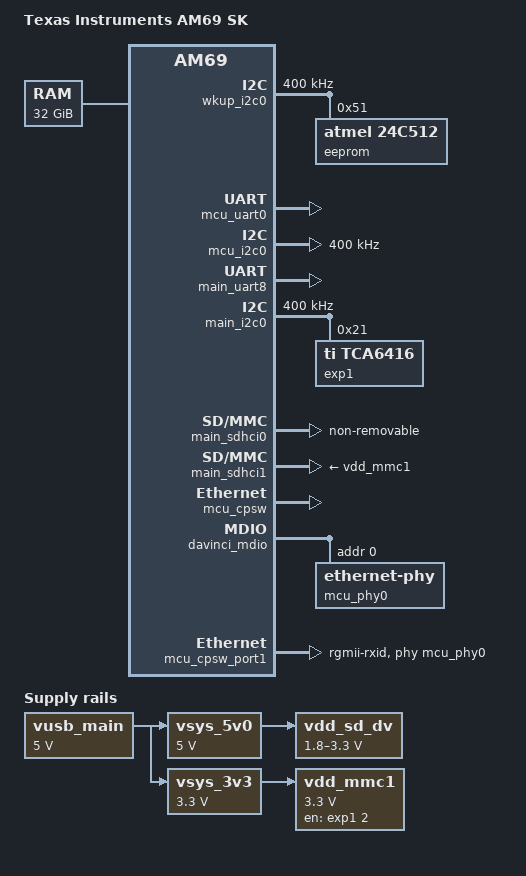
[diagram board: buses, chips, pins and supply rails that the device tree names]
/dts-v1/;
#include <dt-bindings/net/ti-dp83867.h>
#include <dt-bindings/gpio/gpio.h>
#include "k3-j784s4.dtsi"
/ {
	compatible = "ti,am69-sk", "ti,j784s4";
	model = "Texas Instruments AM69 SK";
	chosen {
		stdout-path = "serial2:115200n8";
	};
	aliases {
		serial0 = &wkup_uart0;
		serial1 = &mcu_uart0;
		serial2 = &main_uart8;
		mmc0 = &main_sdhci0;
		mmc1 = &main_sdhci1;
		i2c0 = &wkup_i2c0;
		i2c3 = &main_i2c0;
		ethernet0 = &mcu_cpsw_port1;
	};
	memory@80000000 {
		device_type = "memory";
		reg = <0x00 0x80000000 0x00 0x80000000>,
		      <0x08 0x80000000 0x07 0x80000000>;
	};
	reserved_memory: reserved-memory {
		#address-cells = <2>;
		#size-cells = <2>;
		ranges;
		secure_ddr: optee@9e800000 {
			reg = <0x00 0x9e800000 0x00 0x01800000>;
			no-map;
		};
	};
	vusb_main: regulator-vusb-main5v0 {
		compatible = "regulator-fixed";
		regulator-name = "vusb-main5v0";
		regulator-min-microvolt = <5000000>;
		regulator-max-microvolt = <5000000>;
		regulator-always-on;
		regulator-boot-on;
	};
	vsys_5v0: regulator-vsys5v0 {
		compatible = "regulator-fixed";
		regulator-name = "vsys_5v0";
		regulator-min-microvolt = <5000000>;
		regulator-max-microvolt = <5000000>;
		vin-supply = <&vusb_main>;
		regulator-always-on;
		regulator-boot-on;
	};
	vsys_3v3: regulator-vsys3v3 {
		compatible = "regulator-fixed";
		regulator-name = "vsys_3v3";
		regulator-min-microvolt = <3300000>;
		regulator-max-microvolt = <3300000>;
		vin-supply = <&vusb_main>;
		regulator-always-on;
		regulator-boot-on;
	};
	vdd_mmc1: regulator-sd {
		compatible = "regulator-fixed";
		regulator-name = "vdd_mmc1";
		regulator-min-microvolt = <3300000>;
		regulator-max-microvolt = <3300000>;
		regulator-boot-on;
		enable-active-high;
		vin-supply = <&vsys_3v3>;
		gpio = <&exp1 2 GPIO_ACTIVE_HIGH>;
	};
	vdd_sd_dv: regulator-tlv71033 {
		compatible = "regulator-gpio";
		regulator-name = "tlv71033";
		pinctrl-names = "default";
		pinctrl-0 = <&vdd_sd_dv_pins_default>;
		regulator-min-microvolt = <1800000>;
		regulator-max-microvolt = <3300000>;
		regulator-boot-on;
		vin-supply = <&vsys_5v0>;
		gpios = <&main_gpio0 49 GPIO_ACTIVE_HIGH>;
		states = <1800000 0x0>,
			 <3300000 0x1>;
	};
};
&main_pmx0 {
	bootph-all;
	main_uart8_pins_default: main-uart8-default-pins {
		bootph-all;
		pinctrl-single,pins = <
			J784S4_IOPAD(0x0d0, PIN_INPUT, 11)  
			J784S4_IOPAD(0x0d4, PIN_OUTPUT, 11)  
		>;
	};
	main_i2c0_pins_default: main-i2c0-default-pins {
		pinctrl-single,pins = <
			J784S4_IOPAD(0x0e0, PIN_INPUT_PULLUP, 0)  
			J784S4_IOPAD(0x0e4, PIN_INPUT_PULLUP, 0)  
		>;
	};
	main_mmc1_pins_default: main-mmc1-default-pins {
		bootph-all;
		pinctrl-single,pins = <
			J784S4_IOPAD(0x104, PIN_INPUT, 0)  
			J784S4_IOPAD(0x108, PIN_INPUT, 0)  
			J784S4_IOPAD(0x100, PIN_INPUT, 0)  
			J784S4_IOPAD(0x0fc, PIN_INPUT, 0)  
			J784S4_IOPAD(0x0f8, PIN_INPUT, 0)  
			J784S4_IOPAD(0x0f4, PIN_INPUT, 0)  
			J784S4_IOPAD(0x0f0, PIN_INPUT, 0)  
			J784S4_IOPAD(0x0e8, PIN_INPUT, 8)  
		>;
	};
	vdd_sd_dv_pins_default: vdd-sd-dv-default-pins {
		pinctrl-single,pins = <
			J784S4_IOPAD(0x0C4, PIN_INPUT, 7)  
		>;
	};
	rpi_header_gpio0_pins_default: rpi-header-gpio0-default-pins {
		pinctrl-single,pins = <
			J784S4_IOPAD(0x0BC, PIN_INPUT, 7)  
			J784S4_IOPAD(0x06C, PIN_INPUT, 7)  
			J784S4_IOPAD(0x0B4, PIN_INPUT, 7)  
			J784S4_IOPAD(0x0C0, PIN_INPUT, 7)  
			J784S4_IOPAD(0x00C, PIN_INPUT, 7)  
			J784S4_IOPAD(0x0B8, PIN_INPUT, 7)  
			J784S4_IOPAD(0x090, PIN_INPUT, 7)  
			J784S4_IOPAD(0x0A8, PIN_INPUT, 7)  
			J784S4_IOPAD(0x0A4, PIN_INPUT, 7)  
			J784S4_IOPAD(0x034, PIN_INPUT, 7)  
			J784S4_IOPAD(0x0CC, PIN_INPUT, 7)  
			J784S4_IOPAD(0x08C, PIN_INPUT, 7)  
			J784S4_IOPAD(0x008, PIN_INPUT, 7)  
			J784S4_IOPAD(0x004, PIN_INPUT, 7)  
		>;
	};
};
&wkup_pmx2 {
	bootph-all;
	wkup_uart0_pins_default: wkup-uart0-default-pins {
		bootph-all;
		pinctrl-single,pins = <
			J721S2_WKUP_IOPAD(0x070, PIN_INPUT, 0)  
			J721S2_WKUP_IOPAD(0x074, PIN_INPUT, 0)  
			J721S2_WKUP_IOPAD(0x048, PIN_INPUT, 0)  
			J721S2_WKUP_IOPAD(0x04c, PIN_INPUT, 0)  
		>;
	};
	wkup_i2c0_pins_default: wkup-i2c0-default-pins {
		bootph-all;
		pinctrl-single,pins = <
			J721S2_WKUP_IOPAD(0x98, PIN_INPUT, 0)  
			J721S2_WKUP_IOPAD(0x9c, PIN_INPUT, 0)  
		>;
	};
	mcu_uart0_pins_default: mcu-uart0-default-pins {
		bootph-all;
		pinctrl-single,pins = <
			J784S4_WKUP_IOPAD(0x08c, PIN_INPUT, 0)  
			J784S4_WKUP_IOPAD(0x088, PIN_OUTPUT, 0)  
		>;
	};
	mcu_i2c0_pins_default: mcu-i2c0-default-pins {
		pinctrl-single,pins = <
			J784S4_WKUP_IOPAD(0x0a0, PIN_INPUT_PULLUP, 0)  
			J784S4_WKUP_IOPAD(0x0a4, PIN_INPUT_PULLUP, 0)  
		>;
	};
	mcu_cpsw_pins_default: mcu-cpsw-default-pins {
		pinctrl-single,pins = <
			J784S4_WKUP_IOPAD(0x02c, PIN_INPUT, 0)  
			J784S4_WKUP_IOPAD(0x028, PIN_INPUT, 0)  
			J784S4_WKUP_IOPAD(0x024, PIN_INPUT, 0)  
			J784S4_WKUP_IOPAD(0x020, PIN_INPUT, 0)  
			J784S4_WKUP_IOPAD(0x01c, PIN_INPUT, 0)  
			J784S4_WKUP_IOPAD(0x004, PIN_INPUT, 0)  
			J784S4_WKUP_IOPAD(0x014, PIN_OUTPUT, 0)  
			J784S4_WKUP_IOPAD(0x010, PIN_OUTPUT, 0)  
			J784S4_WKUP_IOPAD(0x00c, PIN_OUTPUT, 0)  
			J784S4_WKUP_IOPAD(0x008, PIN_OUTPUT, 0)  
			J784S4_WKUP_IOPAD(0x018, PIN_OUTPUT, 0)  
			J784S4_WKUP_IOPAD(0x000, PIN_OUTPUT, 0)  
		>;
	};
	mcu_mdio_pins_default: mcu-mdio-default-pins {
		pinctrl-single,pins = <
			J784S4_WKUP_IOPAD(0x034, PIN_OUTPUT, 0)  
			J784S4_WKUP_IOPAD(0x030, PIN_INPUT, 0)  
		>;
	};
	mcu_rpi_hdr1_gpio0_pins_default: mcu-rpi-hdr1-gpio0-default-pins {
		pinctrl-single,pins = <
			J784S4_WKUP_IOPAD(0x118, PIN_INPUT, 7)  
			J784S4_WKUP_IOPAD(0x05c, PIN_INPUT, 7)  
			J784S4_WKUP_IOPAD(0x060, PIN_INPUT, 7)  
			J784S4_WKUP_IOPAD(0x058, PIN_INPUT, 7)  
			J784S4_WKUP_IOPAD(0x0b8, PIN_INPUT, 7)  
			J784S4_WKUP_IOPAD(0x114, PIN_INPUT, 7)  
			J784S4_WKUP_IOPAD(0x094, PIN_INPUT, 7)  
			J784S4_WKUP_IOPAD(0x064, PIN_INPUT, 7)  
			J784S4_WKUP_IOPAD(0x11c, PIN_INPUT, 7)  
		>;
	};
};
&wkup_pmx3 {
	mcu_rpi_hdr2_gpio0_pins_default: mcu-rpi-hdr2-gpio0-default-pins {
		pinctrl-single,pins = <
			J784S4_WKUP_IOPAD(0x0, PIN_INPUT, 7)  
		>;
	};
};
&wkup_uart0 {
	status = "reserved";
	pinctrl-names = "default";
	pinctrl-0 = <&wkup_uart0_pins_default>;
};
&wkup_i2c0 {
	bootph-all;
	status = "okay";
	pinctrl-names = "default";
	pinctrl-0 = <&wkup_i2c0_pins_default>;
	clock-frequency = <400000>;
	eeprom@51 {
		compatible = "atmel,24c512";
		reg = <0x51>;
	};
};
&wkup_gpio0 {
	status = "okay";
	pinctrl-names = "default";
	pinctrl-0 = <&mcu_rpi_hdr1_gpio0_pins_default>, <&mcu_rpi_hdr2_gpio0_pins_default>;
};
&mcu_uart0 {
	bootph-all;
	status = "okay";
	pinctrl-names = "default";
	pinctrl-0 = <&mcu_uart0_pins_default>;
};
&mcu_i2c0 {
	status = "okay";
	pinctrl-names = "default";
	pinctrl-0 = <&mcu_i2c0_pins_default>;
	clock-frequency = <400000>;
};
&main_uart8 {
	bootph-all;
	status = "okay";
	pinctrl-names = "default";
	pinctrl-0 = <&main_uart8_pins_default>;
};
&main_i2c0 {
	status = "okay";
	pinctrl-names = "default";
	pinctrl-0 = <&main_i2c0_pins_default>;
	clock-frequency = <400000>;
	exp1: gpio@21 {
		compatible = "ti,tca6416";
		reg = <0x21>;
		gpio-controller;
		#gpio-cells = <2>;
		gpio-line-names	= "BOARDID_EEPROM_WP", "CAN_STB", "GPIO_uSD_PWR_EN",
				"IO_EXP_MCU_RGMII_RST#", "IO_EXP_PCIe0_4L_PERST#",
				"IO_EXP_PCIe1_M.2_RTSz", "IO_EXP_PCIe3_M.2_RTSz",
				"PM_INA_BUS_EN", "ENET1_EXP_PWRDN", "EXP1_ENET_RSTz",
				"ENET1_I2CMUX_SEL", "PCIe0_CLKREQ#", "PCIe1_M.2_CLKREQ#",
				"PCIe3_M2_CLKREQ#", "PCIe0_PRSNT2#_1", "PCIe0_PRSNT2#_2";
	};
};
&main_sdhci0 {
	bootph-all;
	status = "okay";
	non-removable;
	ti,driver-strength-ohm = <50>;
	disable-wp;
};
&main_sdhci1 {
	bootph-all;
	status = "okay";
	pinctrl-0 = <&main_mmc1_pins_default>;
	pinctrl-names = "default";
	disable-wp;
	vmmc-supply = <&vdd_mmc1>;
	vqmmc-supply = <&vdd_sd_dv>;
};
&main_gpio0 {
	status = "okay";
	pinctrl-names = "default";
	pinctrl-0 = <&rpi_header_gpio0_pins_default>;
};
&mcu_cpsw {
	status = "okay";
	pinctrl-names = "default";
	pinctrl-0 = <&mcu_cpsw_pins_default>, <&mcu_mdio_pins_default>;
};
&davinci_mdio {
	mcu_phy0: ethernet-phy@0 {
		reg = <0>;
		ti,rx-internal-delay = <DP83867_RGMIIDCTL_2_00_NS>;
		ti,fifo-depth = <DP83867_PHYCR_FIFO_DEPTH_4_B_NIB>;
		ti,min-output-impedance;
	};
};
&mcu_cpsw_port1 {
	status = "okay";
	phy-mode = "rgmii-rxid";
	phy-handle = <&mcu_phy0>;
};
